# ESP32-S31 register map
Vendor: ESPRESSIF SYSTEMS (SHANGHAI) CO., LTD.; Series: ESP32 S-Series; File version: 1
CPU: RV32IMAFC r0p0, little endian, no MPU, FPU, 0 interrupt priority bits
Address unit: 32 bits
Registers are 32-bit, read-write, reset 0x0 unless marked. A register's access mark holds for its fields unless they carry their own. Offsets are from the block's base; [hi:lo] are bit positions.

## PMU — PMU Peripheral
Base 0x20704000
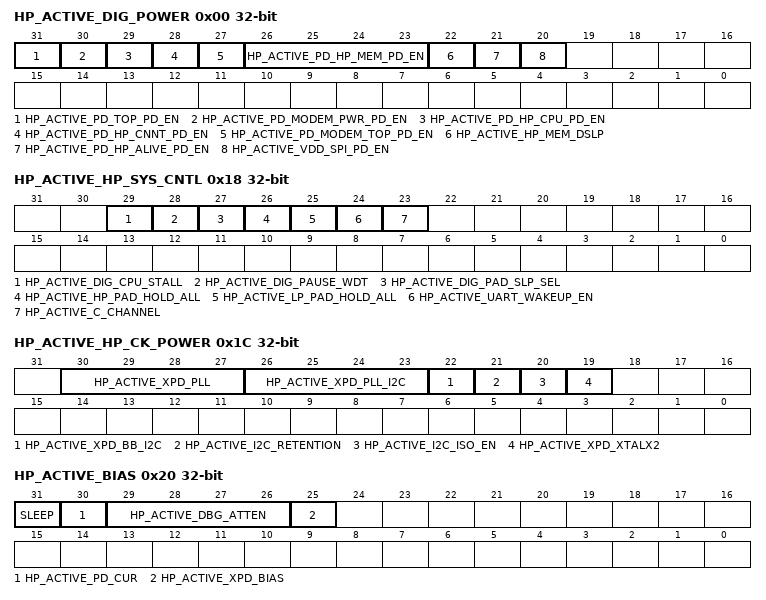
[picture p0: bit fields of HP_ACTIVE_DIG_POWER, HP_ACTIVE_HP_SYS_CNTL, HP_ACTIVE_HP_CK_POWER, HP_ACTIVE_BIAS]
0x00 HP_ACTIVE_DIG_POWER — need_des
  [31] HP_ACTIVE_PD_TOP_PD_EN — need_des
  [30] HP_ACTIVE_PD_MODEM_PWR_PD_EN — need_des
  [29] HP_ACTIVE_PD_HP_CPU_PD_EN — need_des
  [28] HP_ACTIVE_PD_HP_CNNT_PD_EN — need_des
  [27] HP_ACTIVE_PD_MODEM_TOP_PD_EN — need_des
  [26:23] HP_ACTIVE_PD_HP_MEM_PD_EN — need_des
  [22] HP_ACTIVE_HP_MEM_DSLP — need_des
  [21] HP_ACTIVE_PD_HP_ALIVE_PD_EN — need_des
  [20] HP_ACTIVE_VDD_SPI_PD_EN — need_des
0x04 HP_ACTIVE_ICG_HP_FUNC reset 0xFFFFFFFF — need_des
  [31:0] HP_ACTIVE_DIG_ICG_FUNC_EN
0x08 HP_ACTIVE_ICG_HP_APB reset 0xFFFFFFFF — need_des
  [31:0] HP_ACTIVE_DIG_ICG_APB_EN
0x0C HP_ACTIVE_ICG_HP_FUNC1 reset 0xFFFFFFFF — need_des
  [31:0] HP_ACTIVE_DIG_ICG_FUNC1_EN
0x10 HP_ACTIVE_ICG_HP_APB1 reset 0xFFFFFFFF — need_des
  [31:0] HP_ACTIVE_DIG_ICG_APB1_EN
0x14 HP_ACTIVE_ICG_MODEM — need_des
  [31:30] HP_ACTIVE_DIG_ICG_MODEM_CODE
0x18 HP_ACTIVE_HP_SYS_CNTL — need_des
  [29] HP_ACTIVE_DIG_CPU_STALL — need_des
  [28] HP_ACTIVE_DIG_PAUSE_WDT — need_des
  [27] HP_ACTIVE_DIG_PAD_SLP_SEL — need_des
  [26] HP_ACTIVE_HP_PAD_HOLD_ALL — need_des
  [25] HP_ACTIVE_LP_PAD_HOLD_ALL — need_des
  [24] HP_ACTIVE_UART_WAKEUP_EN — need_des
  [23] HP_ACTIVE_C_CHANNEL — need_des
0x1C HP_ACTIVE_HP_CK_POWER — need_des
  [30:27] HP_ACTIVE_XPD_PLL — need_des
  [26:23] HP_ACTIVE_XPD_PLL_I2C — need_des
  [22] HP_ACTIVE_XPD_BB_I2C — need_des
  [21] HP_ACTIVE_I2C_RETENTION — need_des
  [20] HP_ACTIVE_I2C_ISO_EN — need_des
  [19] HP_ACTIVE_XPD_XTALX2 — need_des
0x20 HP_ACTIVE_BIAS — need_des
  [31] SLEEP — need_des
  [30] HP_ACTIVE_PD_CUR — need_des
  [29:26] HP_ACTIVE_DBG_ATTEN — need_des
  [25] HP_ACTIVE_XPD_BIAS — need_des
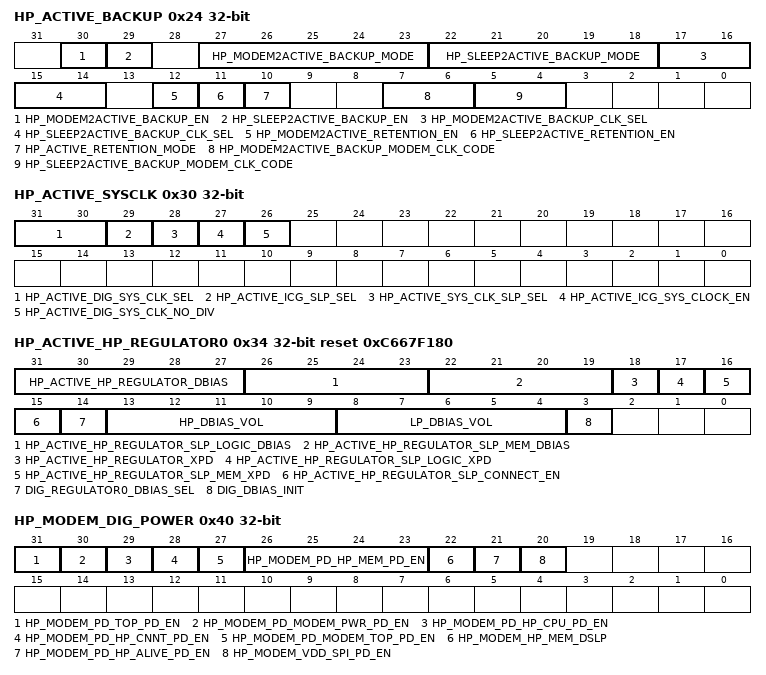
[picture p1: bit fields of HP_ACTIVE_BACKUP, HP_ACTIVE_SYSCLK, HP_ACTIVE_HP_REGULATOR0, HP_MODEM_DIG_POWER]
0x24 HP_ACTIVE_BACKUP — need_des
  [30] HP_MODEM2ACTIVE_BACKUP_EN — need_des
  [29] HP_SLEEP2ACTIVE_BACKUP_EN — need_des
  [27:23] HP_MODEM2ACTIVE_BACKUP_MODE — need_des
  [22:18] HP_SLEEP2ACTIVE_BACKUP_MODE — need_des
  [17:16] HP_MODEM2ACTIVE_BACKUP_CLK_SEL — need_des
  [15:14] HP_SLEEP2ACTIVE_BACKUP_CLK_SEL — need_des
  [12] HP_MODEM2ACTIVE_RETENTION_EN — need_des
  [11] HP_SLEEP2ACTIVE_RETENTION_EN — need_des
  [10] HP_ACTIVE_RETENTION_MODE — need_des
  [7:6] HP_MODEM2ACTIVE_BACKUP_MODEM_CLK_CODE — need_des
  [5:4] HP_SLEEP2ACTIVE_BACKUP_MODEM_CLK_CODE — need_des
0x28 HP_ACTIVE_BACKUP_CLK — need_des
  [31:0] HP_ACTIVE_BACKUP_ICG_FUNC_EN
0x2C HP_ACTIVE_BACKUP1_CLK — need_des
  [31:0] HP_ACTIVE_BACKUP_ICG_FUNC1_EN
0x30 HP_ACTIVE_SYSCLK — need_des
  [31:30] HP_ACTIVE_DIG_SYS_CLK_SEL — need_des
  [29] HP_ACTIVE_ICG_SLP_SEL — need_des
  [28] HP_ACTIVE_SYS_CLK_SLP_SEL — need_des
  [27] HP_ACTIVE_ICG_SYS_CLOCK_EN — need_des
  [26] HP_ACTIVE_DIG_SYS_CLK_NO_DIV — need_des
0x34 HP_ACTIVE_HP_REGULATOR0 access per field reset 0xC667F180 — need_des
  [31:27] HP_ACTIVE_HP_REGULATOR_DBIAS rw — need_des
  [26:23] HP_ACTIVE_HP_REGULATOR_SLP_LOGIC_DBIAS rw — need_des
  [22:19] HP_ACTIVE_HP_REGULATOR_SLP_MEM_DBIAS rw — need_des
  [18] HP_ACTIVE_HP_REGULATOR_XPD rw — need_des
  [17] HP_ACTIVE_HP_REGULATOR_SLP_LOGIC_XPD rw — need_des
  [16] HP_ACTIVE_HP_REGULATOR_SLP_MEM_XPD rw — need_des
  [15] HP_ACTIVE_HP_REGULATOR_SLP_CONNECT_EN rw — need_des
  [14] DIG_REGULATOR0_DBIAS_SEL rw — need_des
  [13:9] HP_DBIAS_VOL ro — need_des
  [8:4] LP_DBIAS_VOL ro — need_des
  [3] DIG_DBIAS_INIT wo — need_des
0x38 HP_ACTIVE_HP_REGULATOR1 — need_des
  [31:8] HP_ACTIVE_HP_REGULATOR_DRV_B
0x3C HP_ACTIVE_XTAL reset 0x80000000 — need_des
  [31] HP_ACTIVE_XPD_XTAL
0x40 HP_MODEM_DIG_POWER — need_des
  [31] HP_MODEM_PD_TOP_PD_EN — need_des
  [30] HP_MODEM_PD_MODEM_PWR_PD_EN — need_des
  [29] HP_MODEM_PD_HP_CPU_PD_EN — need_des
  [28] HP_MODEM_PD_HP_CNNT_PD_EN — need_des
  [27] HP_MODEM_PD_MODEM_TOP_PD_EN — need_des
  [26:23] HP_MODEM_PD_HP_MEM_PD_EN — need_des
  [22] HP_MODEM_HP_MEM_DSLP — need_des
  [21] HP_MODEM_PD_HP_ALIVE_PD_EN — need_des
  [20] HP_MODEM_VDD_SPI_PD_EN — need_des
0x44 HP_MODEM_ICG_HP_FUNC reset 0xFFFFFFFF — need_des
  [31:0] HP_MODEM_DIG_ICG_FUNC_EN
0x48 HP_MODEM_ICG_HP_APB reset 0xFFFFFFFF — need_des
  [31:0] HP_MODEM_DIG_ICG_APB_EN
0x4C HP_MODEM_ICG_HP_FUNC1 reset 0xFFFFFFFF — need_des
  [31:0] HP_MODEM_DIG_ICG_FUNC1_EN
0x50 HP_MODEM_ICG_HP_APB1 reset 0xFFFFFFFF — need_des
  [31:0] HP_MODEM_DIG_ICG_APB1_EN
0x54 HP_MODEM_ICG_MODEM — need_des
  [31:30] HP_MODEM_DIG_ICG_MODEM_CODE
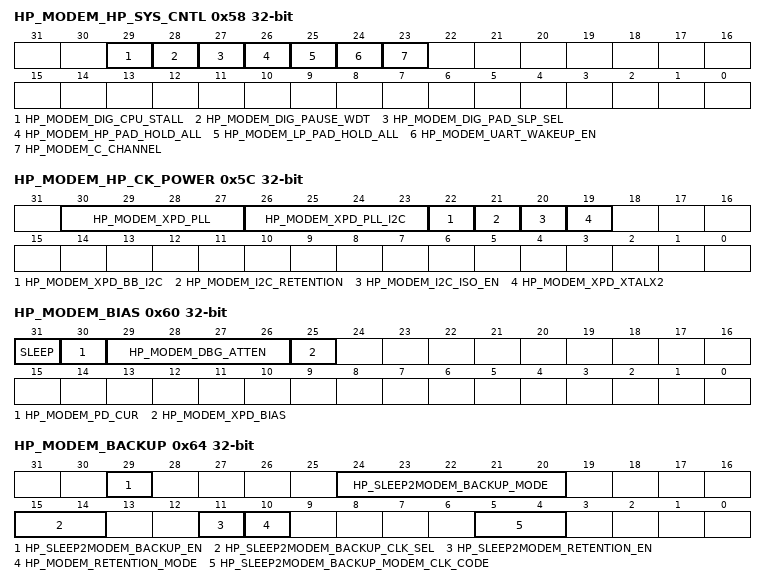
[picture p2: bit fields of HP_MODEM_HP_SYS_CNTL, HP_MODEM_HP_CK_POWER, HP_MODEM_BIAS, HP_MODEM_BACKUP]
0x58 HP_MODEM_HP_SYS_CNTL — need_des
  [29] HP_MODEM_DIG_CPU_STALL — need_des
  [28] HP_MODEM_DIG_PAUSE_WDT — need_des
  [27] HP_MODEM_DIG_PAD_SLP_SEL — need_des
  [26] HP_MODEM_HP_PAD_HOLD_ALL — need_des
  [25] HP_MODEM_LP_PAD_HOLD_ALL — need_des
  [24] HP_MODEM_UART_WAKEUP_EN — need_des
  [23] HP_MODEM_C_CHANNEL — need_des
0x5C HP_MODEM_HP_CK_POWER — need_des
  [30:27] HP_MODEM_XPD_PLL — need_des
  [26:23] HP_MODEM_XPD_PLL_I2C — need_des
  [22] HP_MODEM_XPD_BB_I2C — need_des
  [21] HP_MODEM_I2C_RETENTION — need_des
  [20] HP_MODEM_I2C_ISO_EN — need_des
  [19] HP_MODEM_XPD_XTALX2 — need_des
0x60 HP_MODEM_BIAS — need_des
  [31] SLEEP — need_des
  [30] HP_MODEM_PD_CUR — need_des
  [29:26] HP_MODEM_DBG_ATTEN — need_des
  [25] HP_MODEM_XPD_BIAS — need_des
0x64 HP_MODEM_BACKUP — need_des
  [29] HP_SLEEP2MODEM_BACKUP_EN — need_des
  [24:20] HP_SLEEP2MODEM_BACKUP_MODE — need_des
  [15:14] HP_SLEEP2MODEM_BACKUP_CLK_SEL — need_des
  [11] HP_SLEEP2MODEM_RETENTION_EN — need_des
  [10] HP_MODEM_RETENTION_MODE — need_des
  [5:4] HP_SLEEP2MODEM_BACKUP_MODEM_CLK_CODE — need_des
0x68 HP_MODEM_BACKUP_CLK — need_des
  [31:0] HP_MODEM_BACKUP_ICG_FUNC_EN
0x6C HP_MODEM_BACKUP1_CLK — need_des
  [31:0] HP_MODEM_BACKUP_ICG_FUNC1_EN
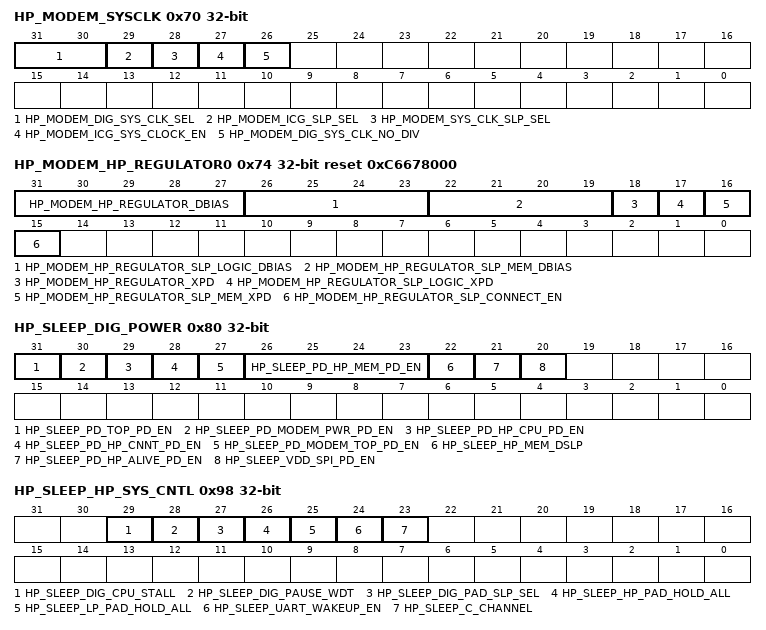
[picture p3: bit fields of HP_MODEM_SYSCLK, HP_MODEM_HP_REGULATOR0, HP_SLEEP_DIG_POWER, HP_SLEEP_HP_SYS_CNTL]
0x70 HP_MODEM_SYSCLK — need_des
  [31:30] HP_MODEM_DIG_SYS_CLK_SEL — need_des
  [29] HP_MODEM_ICG_SLP_SEL — need_des
  [28] HP_MODEM_SYS_CLK_SLP_SEL — need_des
  [27] HP_MODEM_ICG_SYS_CLOCK_EN — need_des
  [26] HP_MODEM_DIG_SYS_CLK_NO_DIV — need_des
0x74 HP_MODEM_HP_REGULATOR0 reset 0xC6678000 — need_des
  [31:27] HP_MODEM_HP_REGULATOR_DBIAS — need_des
  [26:23] HP_MODEM_HP_REGULATOR_SLP_LOGIC_DBIAS — need_des
  [22:19] HP_MODEM_HP_REGULATOR_SLP_MEM_DBIAS — need_des
  [18] HP_MODEM_HP_REGULATOR_XPD — need_des
  [17] HP_MODEM_HP_REGULATOR_SLP_LOGIC_XPD — need_des
  [16] HP_MODEM_HP_REGULATOR_SLP_MEM_XPD — need_des
  [15] HP_MODEM_HP_REGULATOR_SLP_CONNECT_EN — need_des
0x78 HP_MODEM_HP_REGULATOR1 — need_des
  [31:8] HP_MODEM_HP_REGULATOR_DRV_B
0x7C HP_MODEM_XTAL reset 0x80000000 — need_des
  [31] HP_MODEM_XPD_XTAL
0x80 HP_SLEEP_DIG_POWER — need_des
  [31] HP_SLEEP_PD_TOP_PD_EN — need_des
  [30] HP_SLEEP_PD_MODEM_PWR_PD_EN — need_des
  [29] HP_SLEEP_PD_HP_CPU_PD_EN — need_des
  [28] HP_SLEEP_PD_HP_CNNT_PD_EN — need_des
  [27] HP_SLEEP_PD_MODEM_TOP_PD_EN — need_des
  [26:23] HP_SLEEP_PD_HP_MEM_PD_EN — need_des
  [22] HP_SLEEP_HP_MEM_DSLP — need_des
  [21] HP_SLEEP_PD_HP_ALIVE_PD_EN — need_des
  [20] HP_SLEEP_VDD_SPI_PD_EN — need_des
0x84 HP_SLEEP_ICG_HP_FUNC reset 0xFFFFFFFF — need_des
  [31:0] HP_SLEEP_DIG_ICG_FUNC_EN
0x88 HP_SLEEP_ICG_HP_APB reset 0xFFFFFFFF — need_des
  [31:0] HP_SLEEP_DIG_ICG_APB_EN
0x8C HP_SLEEP_ICG_HP_FUNC1 reset 0xFFFFFFFF — need_des
  [31:0] HP_SLEEP_DIG_ICG_FUNC1_EN
0x90 HP_SLEEP_ICG_HP_APB1 reset 0xFFFFFFFF — need_des
  [31:0] HP_SLEEP_DIG_ICG_APB1_EN
0x94 HP_SLEEP_ICG_MODEM — need_des
  [31:30] HP_SLEEP_DIG_ICG_MODEM_CODE
0x98 HP_SLEEP_HP_SYS_CNTL — need_des
  [29] HP_SLEEP_DIG_CPU_STALL — need_des
  [28] HP_SLEEP_DIG_PAUSE_WDT — need_des
  [27] HP_SLEEP_DIG_PAD_SLP_SEL — need_des
  [26] HP_SLEEP_HP_PAD_HOLD_ALL — need_des
  [25] HP_SLEEP_LP_PAD_HOLD_ALL — need_des
  [24] HP_SLEEP_UART_WAKEUP_EN — need_des
  [23] HP_SLEEP_C_CHANNEL — need_des
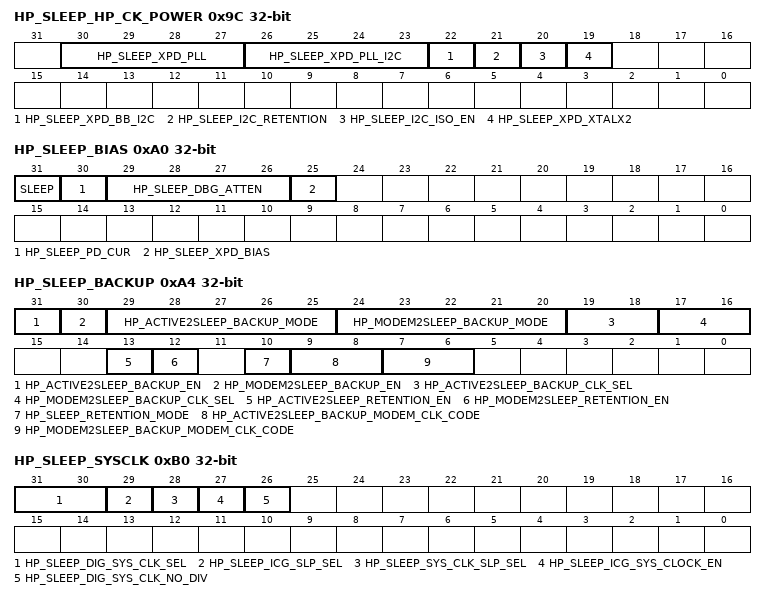
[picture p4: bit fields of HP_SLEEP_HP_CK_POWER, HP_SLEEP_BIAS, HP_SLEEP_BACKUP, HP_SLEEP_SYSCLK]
0x9C HP_SLEEP_HP_CK_POWER — need_des
  [30:27] HP_SLEEP_XPD_PLL — need_des
  [26:23] HP_SLEEP_XPD_PLL_I2C — need_des
  [22] HP_SLEEP_XPD_BB_I2C — need_des
  [21] HP_SLEEP_I2C_RETENTION — need_des
  [20] HP_SLEEP_I2C_ISO_EN — need_des
  [19] HP_SLEEP_XPD_XTALX2 — need_des
0xA0 HP_SLEEP_BIAS — need_des
  [31] SLEEP — need_des
  [30] HP_SLEEP_PD_CUR — need_des
  [29:26] HP_SLEEP_DBG_ATTEN — need_des
  [25] HP_SLEEP_XPD_BIAS — need_des
0xA4 HP_SLEEP_BACKUP — need_des
  [31] HP_ACTIVE2SLEEP_BACKUP_EN — need_des
  [30] HP_MODEM2SLEEP_BACKUP_EN — need_des
  [29:25] HP_ACTIVE2SLEEP_BACKUP_MODE — need_des
  [24:20] HP_MODEM2SLEEP_BACKUP_MODE — need_des
  [19:18] HP_ACTIVE2SLEEP_BACKUP_CLK_SEL — need_des
  [17:16] HP_MODEM2SLEEP_BACKUP_CLK_SEL — need_des
  [13] HP_ACTIVE2SLEEP_RETENTION_EN — need_des
  [12] HP_MODEM2SLEEP_RETENTION_EN — need_des
  [10] HP_SLEEP_RETENTION_MODE — need_des
  [9:8] HP_ACTIVE2SLEEP_BACKUP_MODEM_CLK_CODE — need_des
  [7:6] HP_MODEM2SLEEP_BACKUP_MODEM_CLK_CODE — need_des
0xA8 HP_SLEEP_BACKUP_CLK — need_des
  [31:0] HP_SLEEP_BACKUP_ICG_FUNC_EN
0xAC HP_SLEEP_BACKUP1_CLK — need_des
  [31:0] HP_SLEEP_BACKUP_ICG_FUNC1_EN
0xB0 HP_SLEEP_SYSCLK — need_des
  [31:30] HP_SLEEP_DIG_SYS_CLK_SEL — need_des
  [29] HP_SLEEP_ICG_SLP_SEL — need_des
  [28] HP_SLEEP_SYS_CLK_SLP_SEL — need_des
  [27] HP_SLEEP_ICG_SYS_CLOCK_EN — need_des
  [26] HP_SLEEP_DIG_SYS_CLK_NO_DIV — need_des
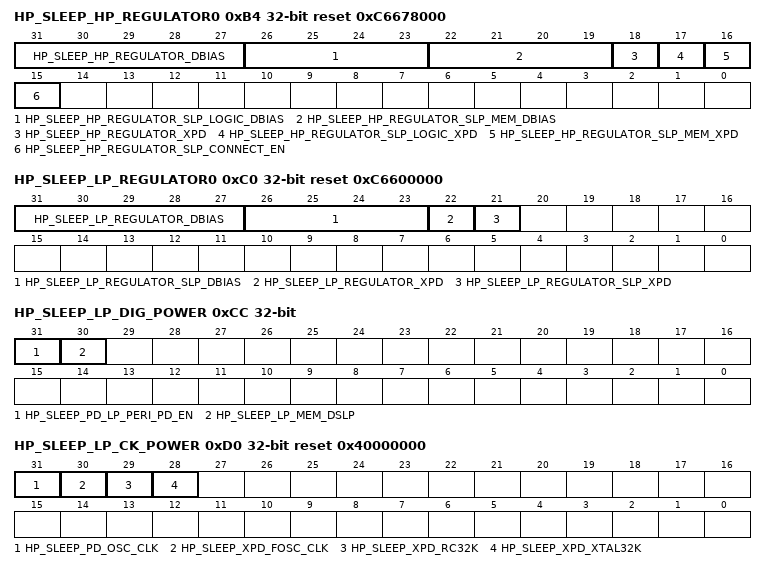
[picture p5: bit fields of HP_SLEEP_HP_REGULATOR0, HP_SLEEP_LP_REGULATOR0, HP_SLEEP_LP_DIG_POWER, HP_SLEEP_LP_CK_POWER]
0xB4 HP_SLEEP_HP_REGULATOR0 reset 0xC6678000 — need_des
  [31:27] HP_SLEEP_HP_REGULATOR_DBIAS — need_des
  [26:23] HP_SLEEP_HP_REGULATOR_SLP_LOGIC_DBIAS — need_des
  [22:19] HP_SLEEP_HP_REGULATOR_SLP_MEM_DBIAS — need_des
  [18] HP_SLEEP_HP_REGULATOR_XPD — need_des
  [17] HP_SLEEP_HP_REGULATOR_SLP_LOGIC_XPD — need_des
  [16] HP_SLEEP_HP_REGULATOR_SLP_MEM_XPD — need_des
  [15] HP_SLEEP_HP_REGULATOR_SLP_CONNECT_EN — need_des
0xB8 HP_SLEEP_HP_REGULATOR1 — need_des
  [31:8] HP_SLEEP_HP_REGULATOR_DRV_B
0xBC HP_SLEEP_XTAL reset 0x80000000 — need_des
  [31] HP_SLEEP_XPD_XTAL
0xC0 HP_SLEEP_LP_REGULATOR0 reset 0xC6600000 — need_des
  [31:27] HP_SLEEP_LP_REGULATOR_DBIAS — need_des
  [26:23] HP_SLEEP_LP_REGULATOR_SLP_DBIAS — need_des
  [22] HP_SLEEP_LP_REGULATOR_XPD — need_des
  [21] HP_SLEEP_LP_REGULATOR_SLP_XPD — need_des
0xC4 HP_SLEEP_LP_REGULATOR1 — need_des
  [31:28] HP_SLEEP_LP_REGULATOR_DRV_B
0xC8 HP_SLEEP_LP_DCDC_RESERVE wo — need_des
  [31:0] PMU_HP_SLEEP_LP_DCDC_RESERVE
0xCC HP_SLEEP_LP_DIG_POWER — need_des
  [31] HP_SLEEP_PD_LP_PERI_PD_EN — need_des
  [30] HP_SLEEP_LP_MEM_DSLP — need_des
0xD0 HP_SLEEP_LP_CK_POWER reset 0x40000000 — need_des
  [31] HP_SLEEP_PD_OSC_CLK — need_des
  [30] HP_SLEEP_XPD_FOSC_CLK — need_des
  [29] HP_SLEEP_XPD_RC32K — need_des
  [28] HP_SLEEP_XPD_XTAL32K — need_des
0xD4 LP_SLEEP_LP_BIAS_RESERVE wo — need_des
  [31:0] PMU_LP_SLEEP_LP_BIAS_RESERVE
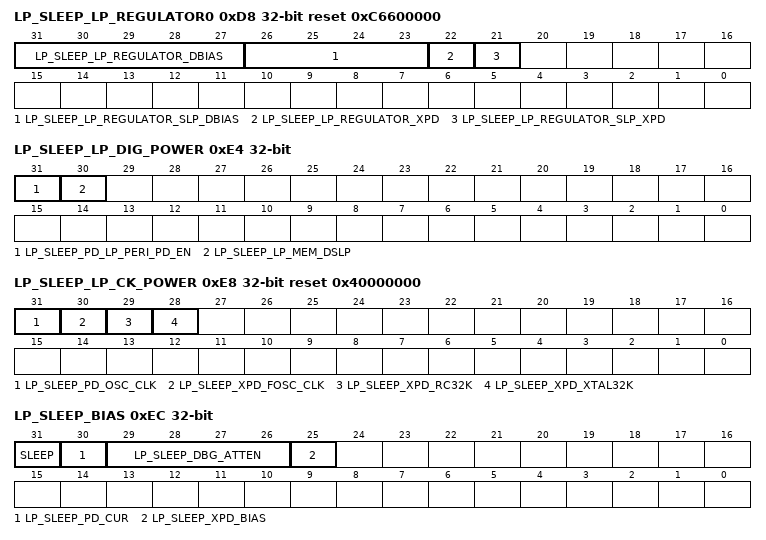
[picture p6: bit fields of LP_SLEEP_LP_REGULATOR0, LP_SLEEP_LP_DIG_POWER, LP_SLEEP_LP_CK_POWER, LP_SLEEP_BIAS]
0xD8 LP_SLEEP_LP_REGULATOR0 reset 0xC6600000 — need_des
  [31:27] LP_SLEEP_LP_REGULATOR_DBIAS — need_des
  [26:23] LP_SLEEP_LP_REGULATOR_SLP_DBIAS — need_des
  [22] LP_SLEEP_LP_REGULATOR_XPD — need_des
  [21] LP_SLEEP_LP_REGULATOR_SLP_XPD — need_des
0xDC LP_SLEEP_LP_REGULATOR1 — need_des
  [31:28] LP_SLEEP_LP_REGULATOR_DRV_B
0xE0 LP_SLEEP_XTAL reset 0x80000000 — need_des
  [31] LP_SLEEP_XPD_XTAL
0xE4 LP_SLEEP_LP_DIG_POWER — need_des
  [31] LP_SLEEP_PD_LP_PERI_PD_EN — need_des
  [30] LP_SLEEP_LP_MEM_DSLP — need_des
0xE8 LP_SLEEP_LP_CK_POWER reset 0x40000000 — need_des
  [31] LP_SLEEP_PD_OSC_CLK — need_des
  [30] LP_SLEEP_XPD_FOSC_CLK — need_des
  [29] LP_SLEEP_XPD_RC32K — need_des
  [28] LP_SLEEP_XPD_XTAL32K — need_des
0xEC LP_SLEEP_BIAS — need_des
  [31] SLEEP — need_des
  [30] LP_SLEEP_PD_CUR — need_des
  [29:26] LP_SLEEP_DBG_ATTEN — need_des
  [25] LP_SLEEP_XPD_BIAS — need_des
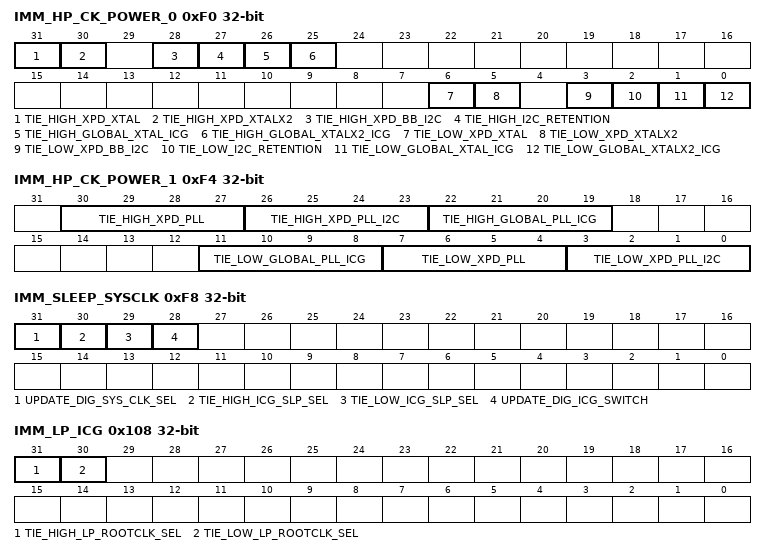
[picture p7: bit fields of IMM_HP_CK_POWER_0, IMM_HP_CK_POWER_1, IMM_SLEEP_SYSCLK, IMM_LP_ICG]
0xF0 IMM_HP_CK_POWER_0 wo — need_des
  [31] TIE_HIGH_XPD_XTAL — need_des
  [30] TIE_HIGH_XPD_XTALX2 — need_des
  [28] TIE_HIGH_XPD_BB_I2C — need_des
  [27] TIE_HIGH_I2C_RETENTION — need_des
  [26] TIE_HIGH_GLOBAL_XTAL_ICG — need_des
  [25] TIE_HIGH_GLOBAL_XTALX2_ICG — need_des
  [6] TIE_LOW_XPD_XTAL — need_des
  [5] TIE_LOW_XPD_XTALX2 — need_des
  [3] TIE_LOW_XPD_BB_I2C — need_des
  [2] TIE_LOW_I2C_RETENTION — need_des
  [1] TIE_LOW_GLOBAL_XTAL_ICG — need_des
  [0] TIE_LOW_GLOBAL_XTALX2_ICG — need_des
0xF4 IMM_HP_CK_POWER_1 wo — need_des
  [30:27] TIE_HIGH_XPD_PLL — need_des
  [26:23] TIE_HIGH_XPD_PLL_I2C — need_des
  [22:19] TIE_HIGH_GLOBAL_PLL_ICG — need_des
  [11:8] TIE_LOW_GLOBAL_PLL_ICG — need_des
  [7:4] TIE_LOW_XPD_PLL — need_des
  [3:0] TIE_LOW_XPD_PLL_I2C — need_des
0xF8 IMM_SLEEP_SYSCLK wo — need_des
  [31] UPDATE_DIG_SYS_CLK_SEL — need_des
  [30] TIE_HIGH_ICG_SLP_SEL — need_des
  [29] TIE_LOW_ICG_SLP_SEL — need_des
  [28] UPDATE_DIG_ICG_SWITCH — need_des
0xFC IMM_HP_FUNC_ICG wo — need_des
  [31] UPDATE_DIG_ICG_FUNC_EN
0x100 IMM_HP_APB_ICG wo — need_des
  [31] UPDATE_DIG_ICG_APB_EN
0x104 IMM_MODEM_ICG wo — need_des
  [31] UPDATE_DIG_ICG_MODEM_EN
0x108 IMM_LP_ICG wo — need_des
  [31] TIE_HIGH_LP_ROOTCLK_SEL — need_des
  [30] TIE_LOW_LP_ROOTCLK_SEL — need_des
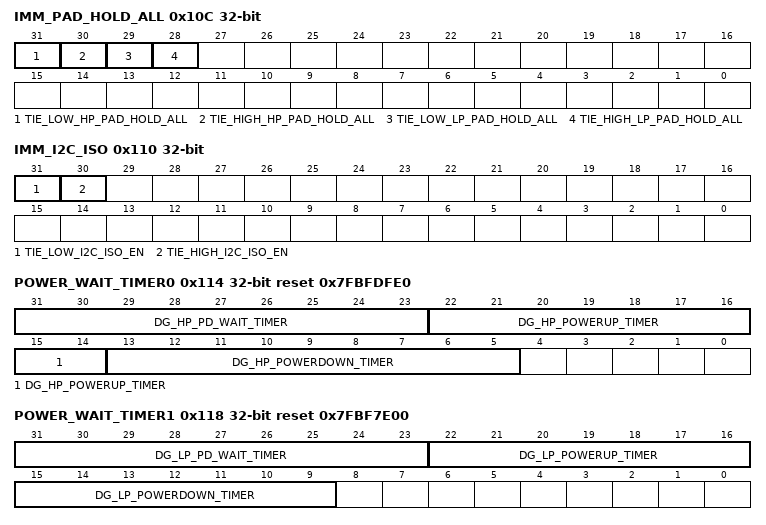
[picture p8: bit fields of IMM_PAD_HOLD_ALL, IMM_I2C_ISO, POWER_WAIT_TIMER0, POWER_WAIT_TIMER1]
0x10C IMM_PAD_HOLD_ALL wo — need_des
  [31] TIE_LOW_HP_PAD_HOLD_ALL — need_des
  [30] TIE_HIGH_HP_PAD_HOLD_ALL — need_des
  [29] TIE_LOW_LP_PAD_HOLD_ALL — need_des
  [28] TIE_HIGH_LP_PAD_HOLD_ALL — need_des
0x110 IMM_I2C_ISO wo — need_des
  [31] TIE_LOW_I2C_ISO_EN — need_des
  [30] TIE_HIGH_I2C_ISO_EN — need_des
0x114 POWER_WAIT_TIMER0 reset 0x7FBFDFE0 — need_des
  [31:23] DG_HP_PD_WAIT_TIMER — need_des
  [22:14] DG_HP_POWERUP_TIMER — need_des
  [13:5] DG_HP_POWERDOWN_TIMER — need_des
0x118 POWER_WAIT_TIMER1 reset 0x7FBF7E00 — need_des
  [31:23] DG_LP_PD_WAIT_TIMER — need_des
  [22:16] DG_LP_POWERUP_TIMER — need_des
  [15:9] DG_LP_POWERDOWN_TIMER — need_des
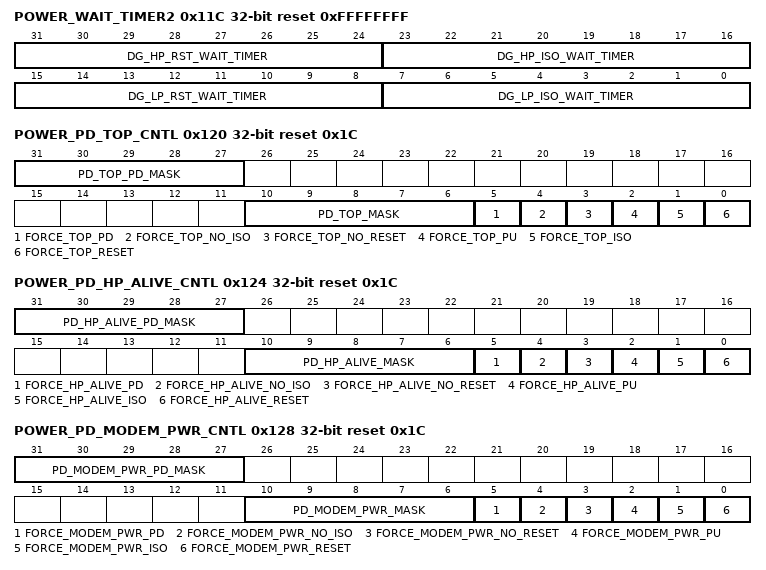
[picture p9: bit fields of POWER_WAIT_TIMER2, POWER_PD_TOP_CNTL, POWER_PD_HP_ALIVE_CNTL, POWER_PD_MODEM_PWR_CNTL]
0x11C POWER_WAIT_TIMER2 reset 0xFFFFFFFF — need_des
  [31:24] DG_HP_RST_WAIT_TIMER — need_des
  [23:16] DG_HP_ISO_WAIT_TIMER — need_des
  [15:8] DG_LP_RST_WAIT_TIMER — need_des
  [7:0] DG_LP_ISO_WAIT_TIMER — need_des
0x120 POWER_PD_TOP_CNTL reset 0x1C — need_des
  [31:27] PD_TOP_PD_MASK — need_des
  [10:6] PD_TOP_MASK — need_des
  [5] FORCE_TOP_PD — need_des
  [4] FORCE_TOP_NO_ISO — need_des
  [3] FORCE_TOP_NO_RESET — need_des
  [2] FORCE_TOP_PU — need_des
  [1] FORCE_TOP_ISO — need_des
  [0] FORCE_TOP_RESET — need_des
0x124 POWER_PD_HP_ALIVE_CNTL reset 0x1C — need_des
  [31:27] PD_HP_ALIVE_PD_MASK — need_des
  [10:6] PD_HP_ALIVE_MASK — need_des
  [5] FORCE_HP_ALIVE_PD — need_des
  [4] FORCE_HP_ALIVE_NO_ISO — need_des
  [3] FORCE_HP_ALIVE_NO_RESET — need_des
  [2] FORCE_HP_ALIVE_PU — need_des
  [1] FORCE_HP_ALIVE_ISO — need_des
  [0] FORCE_HP_ALIVE_RESET — need_des
0x128 POWER_PD_MODEM_PWR_CNTL reset 0x1C — need_des
  [31:27] PD_MODEM_PWR_PD_MASK — need_des
  [10:6] PD_MODEM_PWR_MASK — need_des
  [5] FORCE_MODEM_PWR_PD — need_des
  [4] FORCE_MODEM_PWR_NO_ISO — need_des
  [3] FORCE_MODEM_PWR_NO_RESET — need_des
  [2] FORCE_MODEM_PWR_PU — need_des
  [1] FORCE_MODEM_PWR_ISO — need_des
  [0] FORCE_MODEM_PWR_RESET — need_des
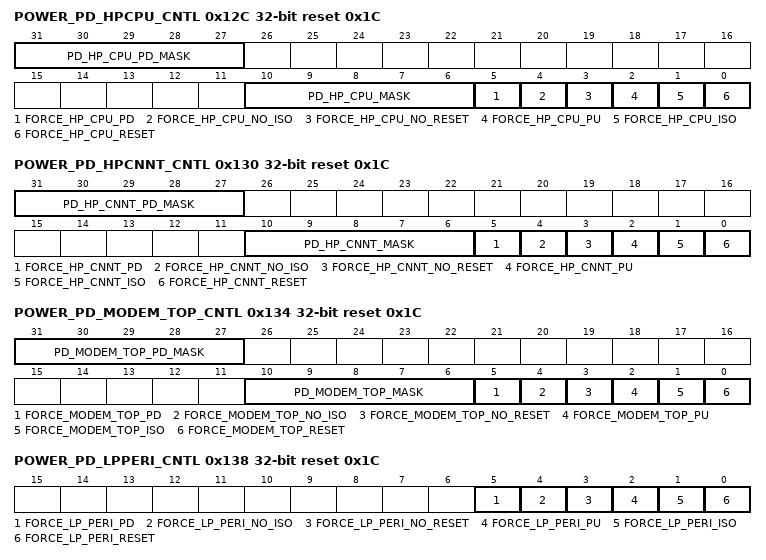
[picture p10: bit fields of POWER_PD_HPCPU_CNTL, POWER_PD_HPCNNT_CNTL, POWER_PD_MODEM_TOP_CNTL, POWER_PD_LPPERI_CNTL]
0x12C POWER_PD_HPCPU_CNTL reset 0x1C — need_des
  [31:27] PD_HP_CPU_PD_MASK — need_des
  [10:6] PD_HP_CPU_MASK — need_des
  [5] FORCE_HP_CPU_PD — need_des
  [4] FORCE_HP_CPU_NO_ISO — need_des
  [3] FORCE_HP_CPU_NO_RESET — need_des
  [2] FORCE_HP_CPU_PU — need_des
  [1] FORCE_HP_CPU_ISO — need_des
  [0] FORCE_HP_CPU_RESET — need_des
0x130 POWER_PD_HPCNNT_CNTL reset 0x1C — need_des
  [31:27] PD_HP_CNNT_PD_MASK — need_des
  [10:6] PD_HP_CNNT_MASK — need_des
  [5] FORCE_HP_CNNT_PD — need_des
  [4] FORCE_HP_CNNT_NO_ISO — need_des
  [3] FORCE_HP_CNNT_NO_RESET — need_des
  [2] FORCE_HP_CNNT_PU — need_des
  [1] FORCE_HP_CNNT_ISO — need_des
  [0] FORCE_HP_CNNT_RESET — need_des
0x134 POWER_PD_MODEM_TOP_CNTL reset 0x1C — need_des
  [31:27] PD_MODEM_TOP_PD_MASK — need_des
  [10:6] PD_MODEM_TOP_MASK — need_des
  [5] FORCE_MODEM_TOP_PD — need_des
  [4] FORCE_MODEM_TOP_NO_ISO — need_des
  [3] FORCE_MODEM_TOP_NO_RESET — need_des
  [2] FORCE_MODEM_TOP_PU — need_des
  [1] FORCE_MODEM_TOP_ISO — need_des
  [0] FORCE_MODEM_TOP_RESET — need_des
0x138 POWER_PD_LPPERI_CNTL reset 0x1C — need_des
  [5] FORCE_LP_PERI_PD — need_des
  [4] FORCE_LP_PERI_NO_ISO — need_des
  [3] FORCE_LP_PERI_NO_RESET — need_des
  [2] FORCE_LP_PERI_PU — need_des
  [1] FORCE_LP_PERI_ISO — need_des
  [0] FORCE_LP_PERI_RESET — need_des
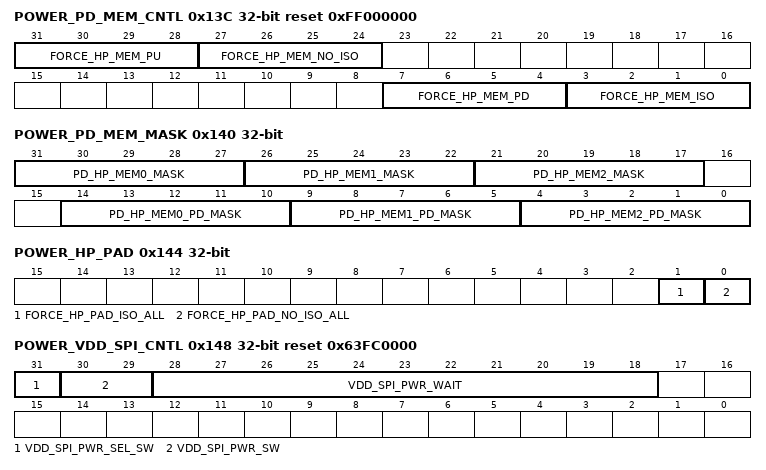
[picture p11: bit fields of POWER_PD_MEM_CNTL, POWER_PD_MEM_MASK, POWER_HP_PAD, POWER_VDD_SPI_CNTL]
0x13C POWER_PD_MEM_CNTL reset 0xFF000000 — need_des
  [31:28] FORCE_HP_MEM_PU — need_des
  [27:24] FORCE_HP_MEM_NO_ISO — need_des
  [7:4] FORCE_HP_MEM_PD — need_des
  [3:0] FORCE_HP_MEM_ISO — need_des
0x140 POWER_PD_MEM_MASK — need_des
  [31:27] PD_HP_MEM0_MASK — need_des
  [26:22] PD_HP_MEM1_MASK — need_des
  [21:17] PD_HP_MEM2_MASK — need_des
  [14:10] PD_HP_MEM0_PD_MASK — need_des
  [9:5] PD_HP_MEM1_PD_MASK — need_des
  [4:0] PD_HP_MEM2_PD_MASK — need_des
0x144 POWER_HP_PAD — need_des
  [1] FORCE_HP_PAD_ISO_ALL — need_des
  [0] FORCE_HP_PAD_NO_ISO_ALL — need_des
0x148 POWER_VDD_SPI_CNTL reset 0x63FC0000 — need_des
  [31] VDD_SPI_PWR_SEL_SW — need_des
  [30:29] VDD_SPI_PWR_SW — need_des
  [28:18] VDD_SPI_PWR_WAIT — need_des
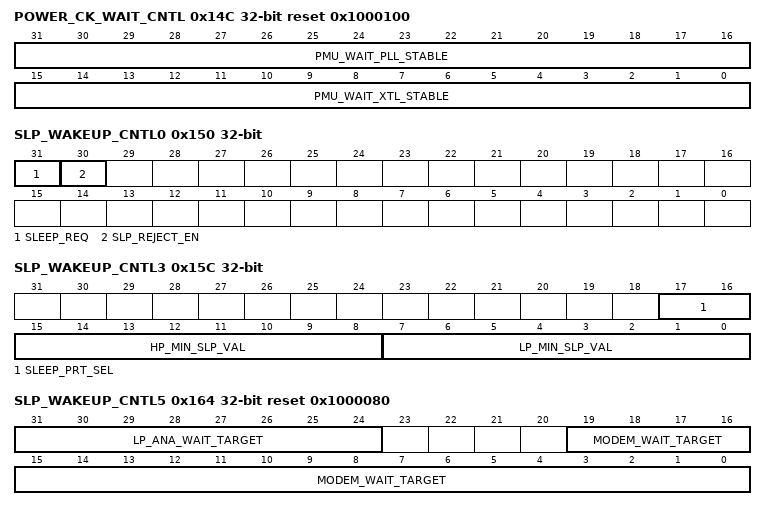
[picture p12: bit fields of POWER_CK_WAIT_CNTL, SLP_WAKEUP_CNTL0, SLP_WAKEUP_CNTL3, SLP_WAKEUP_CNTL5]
0x14C POWER_CK_WAIT_CNTL reset 0x1000100 — need_des
  [31:16] PMU_WAIT_PLL_STABLE — need_des
  [15:0] PMU_WAIT_XTL_STABLE — need_des
0x150 SLP_WAKEUP_CNTL0 access per field — need_des
  [31] SLEEP_REQ wo — need_des
  [30] SLP_REJECT_EN rw — need_des
0x154 SLP_WAKEUP_CNTL1 — need_des
  [31:0] SLEEP_REJECT_ENA
0x158 SLP_WAKEUP_CNTL2 — need_des
  [31:0] WAKEUP_ENA
0x15C SLP_WAKEUP_CNTL3 — need_des
  [17:16] SLEEP_PRT_SEL — need_des
  [15:8] HP_MIN_SLP_VAL — need_des
  [7:0] LP_MIN_SLP_VAL — need_des
0x160 SLP_WAKEUP_CNTL4 wo — need_des
  [31] SLP_REJECT_CAUSE_CLR
0x164 SLP_WAKEUP_CNTL5 reset 0x1000080 — need_des
  [31:24] LP_ANA_WAIT_TARGET — need_des
  [19:0] MODEM_WAIT_TARGET — need_des
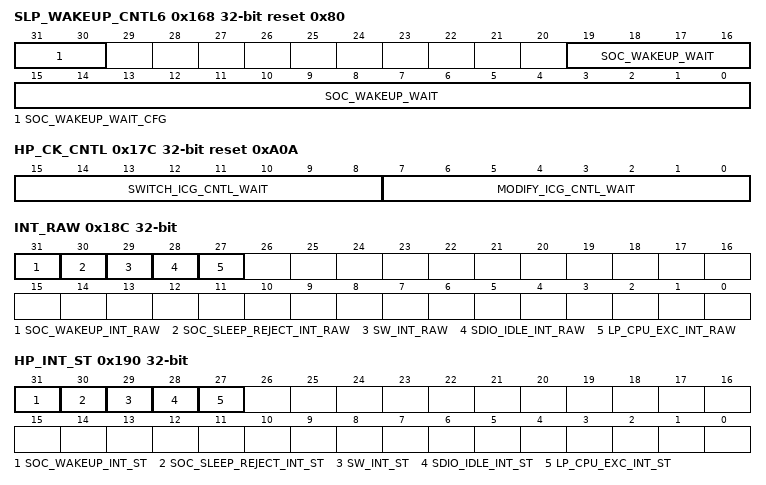
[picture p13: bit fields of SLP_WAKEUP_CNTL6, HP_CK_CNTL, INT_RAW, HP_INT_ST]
0x168 SLP_WAKEUP_CNTL6 reset 0x80 — need_des
  [31:30] SOC_WAKEUP_WAIT_CFG — need_des
  [19:0] SOC_WAKEUP_WAIT — need_des
0x16C SLP_WAKEUP_CNTL7 reset 0x10000 — need_des
  [31:16] ANA_WAIT_TARGET
0x170 SLP_WAKEUP_STATUS0 ro — need_des
  [31:0] WAKEUP_CAUSE
0x174 SLP_WAKEUP_STATUS1 ro — need_des
  [31:0] REJECT_CAUSE
0x178 HP_CK_POWERON reset 0x32 — need_des
  [7:0] I2C_POR_WAIT_TARGET
0x17C HP_CK_CNTL reset 0xA0A — need_des
  [15:8] SWITCH_ICG_CNTL_WAIT — need_des
  [7:0] MODIFY_ICG_CNTL_WAIT — need_des
0x180 POR_STATUS ro reset 0x80000000 — need_des
  [31] POR_DONE
0x184 RF_PWC — need_des
  [31:16] XPD_RF_CIRCUIT
0x188 BACKUP_CFG reset 0x80000000 — need_des
  [31] BACKUP_SYS_CLK_NO_DIV
0x18C INT_RAW — need_des
  [31] SOC_WAKEUP_INT_RAW — need_des
  [30] SOC_SLEEP_REJECT_INT_RAW — need_des
  [29] SW_INT_RAW — need_des
  [28] SDIO_IDLE_INT_RAW — need_des
  [27] LP_CPU_EXC_INT_RAW — need_des
0x190 HP_INT_ST ro — need_des
  [31] SOC_WAKEUP_INT_ST — need_des
  [30] SOC_SLEEP_REJECT_INT_ST — need_des
  [29] SW_INT_ST — need_des
  [28] SDIO_IDLE_INT_ST — need_des
  [27] LP_CPU_EXC_INT_ST — need_des
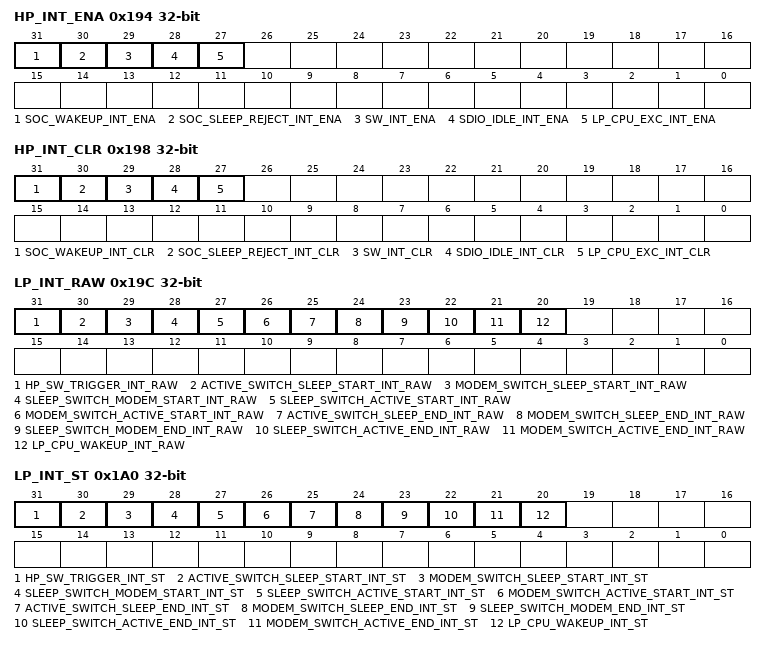
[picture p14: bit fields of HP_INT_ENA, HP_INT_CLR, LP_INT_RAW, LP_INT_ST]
0x194 HP_INT_ENA — need_des
  [31] SOC_WAKEUP_INT_ENA — need_des
  [30] SOC_SLEEP_REJECT_INT_ENA — need_des
  [29] SW_INT_ENA — need_des
  [28] SDIO_IDLE_INT_ENA — need_des
  [27] LP_CPU_EXC_INT_ENA — need_des
0x198 HP_INT_CLR wo — need_des
  [31] SOC_WAKEUP_INT_CLR — need_des
  [30] SOC_SLEEP_REJECT_INT_CLR — need_des
  [29] SW_INT_CLR — need_des
  [28] SDIO_IDLE_INT_CLR — need_des
  [27] LP_CPU_EXC_INT_CLR — need_des
0x19C LP_INT_RAW — need_des
  [31] HP_SW_TRIGGER_INT_RAW — need_des
  [30] ACTIVE_SWITCH_SLEEP_START_INT_RAW — need_des
  [29] MODEM_SWITCH_SLEEP_START_INT_RAW — need_des
  [28] SLEEP_SWITCH_MODEM_START_INT_RAW — need_des
  [27] SLEEP_SWITCH_ACTIVE_START_INT_RAW — need_des
  [26] MODEM_SWITCH_ACTIVE_START_INT_RAW — need_des
  [25] ACTIVE_SWITCH_SLEEP_END_INT_RAW — need_des
  [24] MODEM_SWITCH_SLEEP_END_INT_RAW — need_des
  [23] SLEEP_SWITCH_MODEM_END_INT_RAW — need_des
  [22] SLEEP_SWITCH_ACTIVE_END_INT_RAW — need_des
  [21] MODEM_SWITCH_ACTIVE_END_INT_RAW — need_des
  [20] LP_CPU_WAKEUP_INT_RAW — need_des
0x1A0 LP_INT_ST ro — need_des
  [31] HP_SW_TRIGGER_INT_ST — need_des
  [30] ACTIVE_SWITCH_SLEEP_START_INT_ST — need_des
  [29] MODEM_SWITCH_SLEEP_START_INT_ST — need_des
  [28] SLEEP_SWITCH_MODEM_START_INT_ST — need_des
  [27] SLEEP_SWITCH_ACTIVE_START_INT_ST — need_des
  [26] MODEM_SWITCH_ACTIVE_START_INT_ST — need_des
  [25] ACTIVE_SWITCH_SLEEP_END_INT_ST — need_des
  [24] MODEM_SWITCH_SLEEP_END_INT_ST — need_des
  [23] SLEEP_SWITCH_MODEM_END_INT_ST — need_des
  [22] SLEEP_SWITCH_ACTIVE_END_INT_ST — need_des
  [21] MODEM_SWITCH_ACTIVE_END_INT_ST — need_des
  [20] LP_CPU_WAKEUP_INT_ST — need_des
0x1A4 LP_INT_ENA — need_des
  [31] HP_SW_TRIGGER_INT_ENA — need_des
  [30] ACTIVE_SWITCH_SLEEP_START_INT_ENA — need_des
  [29] MODEM_SWITCH_SLEEP_START_INT_ENA — need_des
  [28] SLEEP_SWITCH_MODEM_START_INT_ENA — need_des
  [27] SLEEP_SWITCH_ACTIVE_START_INT_ENA — need_des
  [26] MODEM_SWITCH_ACTIVE_START_INT_ENA — need_des
  [25] ACTIVE_SWITCH_SLEEP_END_INT_ENA — need_des
  [24] MODEM_SWITCH_SLEEP_END_INT_ENA — need_des
  [23] SLEEP_SWITCH_MODEM_END_INT_ENA — need_des
  [22] SLEEP_SWITCH_ACTIVE_END_INT_ENA — need_des
  [21] MODEM_SWITCH_ACTIVE_END_INT_ENA — need_des
  [20] LP_CPU_WAKEUP_INT_ENA — need_des
0x1A8 LP_INT_CLR wo — need_des
  [31] HP_SW_TRIGGER_INT_CLR — need_des
  [30] ACTIVE_SWITCH_SLEEP_START_INT_CLR — need_des
  [29] MODEM_SWITCH_SLEEP_START_INT_CLR — need_des
  [28] SLEEP_SWITCH_MODEM_START_INT_CLR — need_des
  [27] SLEEP_SWITCH_ACTIVE_START_INT_CLR — need_des
  [26] MODEM_SWITCH_ACTIVE_START_INT_CLR — need_des
  [25] ACTIVE_SWITCH_SLEEP_END_INT_CLR — need_des
  [24] MODEM_SWITCH_SLEEP_END_INT_CLR — need_des
  [23] SLEEP_SWITCH_MODEM_END_INT_CLR — need_des
  [22] SLEEP_SWITCH_ACTIVE_END_INT_CLR — need_des
  [21] MODEM_SWITCH_ACTIVE_END_INT_CLR — need_des
  [20] LP_CPU_WAKEUP_INT_CLR — need_des
0x1AC LP_CPU_PWR0 access per field reset 0x1FF00000 — need_des
  [31] LP_CPU_SLP_BYPASS_INTR_EN rw — need_des
  [30] LP_CPU_SLP_RESET_EN rw — need_des
  [29] LP_CPU_SLP_STALL_EN rw — need_des
  [28:21] LP_CPU_SLP_STALL_WAIT rw — need_des
  [20] LP_CPU_SLP_STALL_FLAG_EN rw — need_des
  [19] LP_CPU_SLP_WAITI_FLAG_EN rw — need_des
  [18] LP_CPU_FORCE_STALL rw — need_des
  [1] LP_CPU_STALL_RDY ro — need_des
  [0] LP_CPU_WAITI_RDY ro — need_des
0x1B0 LP_CPU_PWR1 wo — need_des
  [31] LP_CPU_SLEEP_REQ
0x1B4 LP_CPU_PWR2 — need_des
  [31:0] LP_CPU_WAKEUP_EN
0x1B8 HP_LP_CPU_COMM wo — need_des
  [31] HP_TRIGGER_LP — need_des
  [30] LP_TRIGGER_HP — need_des
0x1BC HP_REGULATOR_CFG — need_des
  [31] DIG_REGULATOR_EN_CAL
0x1C0 MAIN_STATE ro reset 0x8100800 — need_des
  [31:25] PMU_MAIN_CUR_ST_STATE — need_des
  [24:18] PMU_MAIN_TAR_ST_STATE — need_des
  [17:11] PMU_MAIN_LAST_ST_STATE — need_des
0x1C4 PWR_STATE ro reset 0x802000 — need_des
  [31:23] PMU_HP_PWR_ST_STATE — need_des
  [22:18] PMU_LP_PWR_ST_STATE — need_des
  [17:13] PMU_BACKUP_ST_STATE — need_des
0x1C8 CLK_STATE0 ro reset 0x2 — need_des
  [31] PMU_ANA_XPD_XTAL_STATE — need_des
  [28] PMU_ANA_XPD_BB_I2C_STATE — need_des
  [27] PMU_ANA_I2C_RETENTION_STATE — need_des
  [26] PMU_ANA_I2C_ISO_EN_STATE — need_des
  [24] PMU_ICG_GLOBAL_XTAL_STATE — need_des
  [23] PMU_ICG_SLP_SEL_STATE — need_des
  [22:21] PMU_ICG_MODEM_CODE_STATE — need_des
  [20] PMU_ICG_MODEM_SWITCH_STATE — need_des
  [19] PMU_ICG_SYS_CLK_EN_STATE — need_des
  [18] PMU_SYS_CLK_NO_DIV_STATE — need_des
  [17:16] PMU_SYS_CLK_SEL_STATE — need_des
  [15] PMU_SYS_CLK_SLP_SEL_STATE — need_des
  [1] STABLE_XPD_XTAL_STATE — need_des
0x1CC CLK_STATE1 ro reset 0xFFFFFFFF — need_des
  [31:0] PMU_ICG_FUNC_EN_STATE
0x1D0 CLK_STATE2 ro reset 0xFFFFFFFF — need_des
  [31:0] PMU_ICG_APB_EN_STATE
0x1D4 CLK_STATE3 ro reset 0xFFFF0000 — need_des
  [31:28] PMU_ANA_XPD_PLL_STATE — need_des
  [27:24] PMU_ANA_XPD_PLL_I2C_STATE — need_des
  [23:20] PMU_ICG_GLOBAL_PLL_STATE — need_des
  [19:16] STABLE_XPD_PLL_STATE — need_des
0x1D8 VDD_SPI_STATUS ro — need_des
  [31] STABLE_VDD_SPI_PWR_DRV — need_des
  [30] FLASH_POWER_SEL_DONE — need_des
  [29] FLASH_POWER_READY — need_des
0x1DC VDD_SPI_CFG reset 0x28804B0 — need_des
  [31:22] FLASH_COOLDOWN_TIME — need_des
  [21:12] FLASH_STABLE_TIME — need_des
  [11:2] FLASH_SWITCH_TIME — need_des
  [1] FLASH_POWER_SEL_SW_CTRL — need_des
  [0] FLASH_SW_POWER_SEL — need_des
0x1E0 VDD_SPI_DISCHARGE_CFG reset 0x8 — need_des
  [9:0] FLASH_DISCHARGE_TIME
0x1E4 VDD_SDIO_CFG reset 0x28 — need_des
  [11:2] SDIO_SWITCH_TIME — need_des
  [1] SDIO_POWER_SEL_SW_CTRL — need_des
  [0] SDIO_SW_POWER_SEL — need_des
0x1E8 PSRAM_CFG — need_des
  [31] PSRAM_XPD
0x1EC CPU_STALL_SW — need_des
  [31:24] HPCORE0_SW_STALL_CODE — need_des
  [23:16] HPCORE1_SW_STALL_CODE — need_des
0x1F0 EXT_WAKEUP_LV — need_des
  [20:0] EXT_WAKEUP_LV
0x1F4 EXT_WAKEUP_SEL — need_des
  [20:0] EXT_WAKEUP_SEL
0x1F8 EXT_WAKEUP_ST ro — need_des
  [20:0] EXT_WAKEUP_STATUS
0x1FC EXT_WAKEUP_CNTL — need_des
  [31] EXT_WAKEUP_FILTER — need_des
  [30] EXT_WAKEUP_STATUS_CLR — need_des
0x200 SDIO_WAKEUP_CNTL reset 0x3FF — control the wait timer register for sdio wakeup control
  [9:0] SDIO_ACT_DNUM — delay number config for sdio wakeup control
0x204 TOUCH_PWR_CTRL — need_des
  [31] TOUCH_FORCE_DONE — need_des
  [30] TOUCH_SLEEP_TIMER_EN — need_des
  [29:21] TOUCH_WAIT_CYCLES — need_des
  [15:0] TOUCH_SLEEP_CYCLES — need_des
0x208 ANA_PERI_PWR_CTRL reset 0x40000000 — need_des
  [31] RSTB_PERIF_I2C — need_des
  [30] XPD_PERIF_I2C — need_des
0x20C RDN_ECO — used for future potential eco, others don't care
  [31] PMU_RDN_ECO_EN — need_des
0x210 PUF_MEM_CTRL reset 0x1 — used for future potential eco, others don't care
  [2] PUF_MEM_DISCHARGE — need_des
  [1] PUF_MEM_ISO — need_des
  [0] PUF_MEM_PSW — need_des
0x214 SLP_WAKEUP_CNTL8 — need_des
  [17:15] PD_HP_ALIVE_PU_DELT_TIMER — need_des
  [14:12] PD_HP_CNNT_PU_DELT_TIMER — need_des
  [11:9] PD_MODEM_PWR_PU_DELT_TIMER — need_des
  [8:6] PD_MODEM_TOP_PU_DELT_TIMER — need_des
  [5:3] PD_HP_CPU_PU_DELT_TIMER — need_des
  [2:0] PD_TOP_PU_DELT_TIMER — need_des
0x218 EXT_LDO_CTRL — need_des
  [9:6] EXT_LDO_DREF — need_des
  [5:3] EXT_LDO_MUL — need_des
  [2] EXT_CUR_LIM — need_des
  [1] EXT_LDO_EN_VDET — need_des
  [0] EXT_LDO_TIE_HIGH — need_des
0x21C DEBUG_RO ro — used for future potential eco, others don't care
  [6] IO_0P2A_OVDET — need_des
  [5:0] CPU_PWR_STATE — need_des
0x220 LPCPU_WAKEUP_CAUSE ro — need_des
0x224 BACKUP_WAIT_TARGET reset 0xF — need_des
  [3:0] BACKUP_WAIT_TARGET
0x3FC DATE reset 0x250902 — need_des
  [31] CLK_EN — need_des
  [30:0] PMU_DATE — need_des
